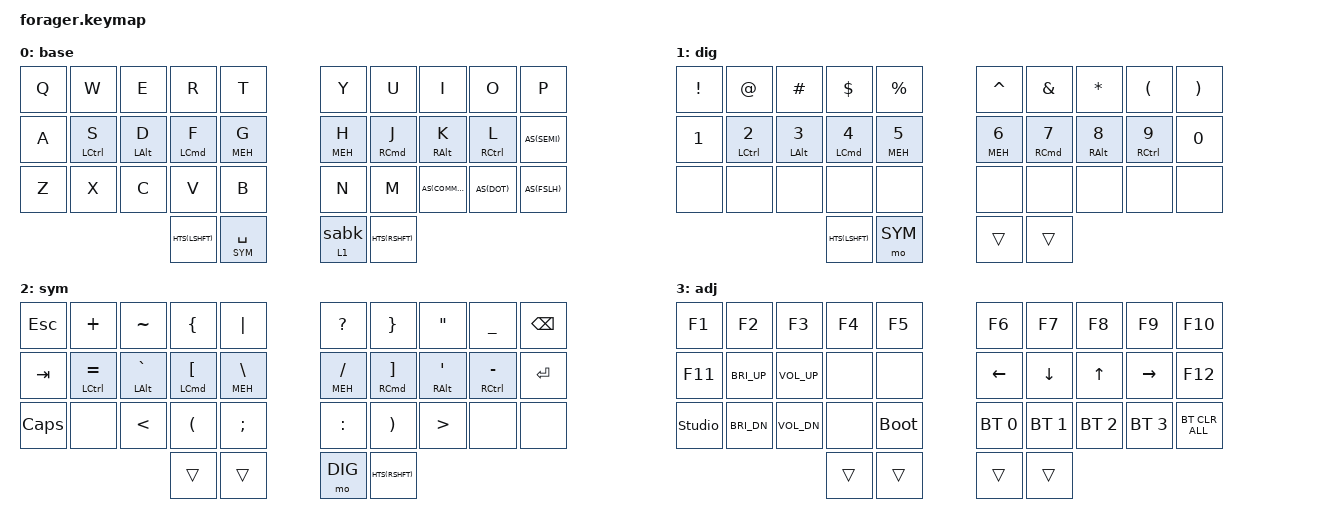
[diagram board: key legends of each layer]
#include <behaviors.dtsi>
#include <dt-bindings/zmk/keys.h>
#include <dt-bindings/zmk/bt.h>
#include <dt-bindings/zmk/outputs.h>

#define BASE 0
#define DIG  1
#define SYM  2
#define ADJ  3

#define AS(keycode) &as LS(keycode) keycode     // Autoshift Macro
#define HTS(keycode) &hts keycode keycode       // Hold tap sticky
#define MEH LS(LC(LALT))

/ {
    behaviors {
        as: auto_shift {
            compatible = "zmk,behavior-hold-tap";
            #binding-cells = <2>;
            tapping-term-ms = <250>;
            require-prior-idle-ms = <100>;
            flavor = "tap-preferred";
            bindings = <&kp>, <&kp>;
        };
        ht: hold_tap {
            compatible = "zmk,behavior-hold-tap";
            #binding-cells = <2>;
            tapping-term-ms = <200>;
            flavor = "balanced";
            bindings = <&kp>, <&kp>;
        };
        sabk: shift_to_alt_backspace {
            compatible = "zmk,behavior-mod-morph";
            #binding-cells = <0>;
            bindings = <&kp BSPC>, <&kp LA(BSPC)>;
            mods = <(MOD_LSFT|MOD_RSFT)>;
        };
        hts: hold_stiky_tap_shift {
            compatible = "zmk,behavior-hold-tap";
            #binding-cells = <2>;
            tapping-term-ms = <200>;
            flavor = "balanced";
            bindings = <&sk>, <&kp>;
        };
        sym_bspc: left_thumb_hold_tap {
            compatible = "zmk,behavior-hold-tap";
            #binding-cells = <2>;
            flavor = "tap-preferred";
            tapping-term-ms = <150>;
            quick-tap-ms = <200>;
            bindings = <&mo>, <&sabk>;
        };
        lhm: left_homerow_mods {
            compatible = "zmk,behavior-hold-tap";
            #binding-cells = <2>;
            flavor = "balanced";
            tapping-term-ms = <280>;
            quick-tap-ms = <175>;
            require-prior-idle-ms = <150>;
            bindings = <&kp>, <&kp>;
            hold-trigger-key-positions = <5 6 7 8 9 15 16 17 18 19 25 26 27 28 29 30 31 32 33>;
        };
        rhm: right_homerow_mods {
            compatible = "zmk,behavior-hold-tap";
            #binding-cells = <2>;
            flavor = "balanced";
            tapping-term-ms = <280>;
            quick-tap-ms = <175>;
            require-prior-idle-ms = <150>;
            bindings = <&kp>, <&kp>;
            hold-trigger-key-positions = <0 1 2 3 4 10 11 12 13 14 20 21 22 23 24 30 31 32 33>;
        };
    };

    combos {
        compatible = "zmk,combos";
        combo_caps {
            timeout-ms = <50>;
            key-positions = <30 33>; // Both shifts
            bindings = <&kp CAPS>;
        };
    };

    conditional_layers {
        compatible = "zmk,conditional-layers";
        tri_layer {
            if-layers = <1 2>;
            then-layer = <3>;
        };
    };

    keymap {
        compatible = "zmk,keymap";

        base {
            bindings = <
            &kp Q           &kp W           &kp E           &kp R           &kp T                                           &kp Y           &kp U           &kp I           &kp O           &kp P
            &kp A           &lhm LCTRL S    &lhm LALT D     &lhm LCMD F     &lhm MEH G                                      &rhm MEH H      &rhm RCMD J     &rhm RALT K     &rhm RCTRL L    AS(SEMI)
            &kp Z           &kp X           &kp C           &kp V           &kp B                                           &kp N           &kp M           AS(COMMA)       AS(DOT)         AS(FSLH)
                                                                            HTS(LSHFT)  &lt SYM SPACE      &sym_bspc 1 0    HTS(RSHFT)
            >;
        };

        dig {
            bindings = <
            /* &kp LS(N1)      &kp LS(N2)      &kp LS(N3)      &kp LS(N4)      &kp LS(N5)                                      &kp LS(N6)      &kp LS(N7)      &kp LS(N8)      &kp LS(N9)      &kp LS(N0) */
            &kp EXCL        &kp AT_SIGN     &kp HASH        &kp DOLLAR      &kp PERCENT                                     &kp CARET       &kp AMPS        &kp ASTRK       &kp LPAR        &kp RPAR
            &kp N1          &lhm LCTRL N2   &lhm LALT N3    &lhm LCMD N4    &lhm MEH N5                                     &rhm MEH N6     &rhm RCMD N7    &rhm RALT N8    &rhm RCTRL N9   &kp N0
            &none           &none           &none           &none           &none                                           &none           &none           &none           &none           &none 
                                                                            HTS(LSHFT)  &mo SYM            &trans           &trans
            >;
        };

        sym {
            bindings = <
            &kp ESC         &kp PLUS         &kp TILDE       &kp LBRC       &kp PIPE                                        &kp QMARK       &kp RBRC        &kp DQT          &kp UNDER        &kp BSPC
            &kp TAB         &lhm LCTRL EQUAL &lhm LALT GRAVE &lhm LCMD LBKT &lhm MEH BSLH                                   &rhm MEH FSLH   &rhm RCMD RBKT  &rhm RALT SQT    &rhm RCTRL MINUS &kp ENTER
            &kp CAPSLOCK    &none            &kp LESS_THAN   &kp LPAR       &kp SEMI                                        &kp COLON       &kp RPAR        &kp GREATER_THAN &none            &none 
                                                                            &trans          &trans           &mo DIG        HTS(RSHFT) 
            >;
        };

        adj {
            bindings = <
            &kp F1          &kp F2          &kp F3          &kp F4          &kp F5                                          &kp F6          &kp F7          &kp F8          &kp F9          &kp F10
            &kp F11         &kp C_BRI_UP    &kp C_VOL_UP    &none           &none                                           &kp LEFT        &kp DOWN        &kp UP          &kp RIGHT       &kp F12
            &studio_unlock  &kp C_BRI_DN    &kp C_VOL_DN    &none           &bootloader                                     &bt BT_SEL 0    &bt BT_SEL 1    &bt BT_SEL 2    &bt BT_SEL 3    &bt BT_CLR_ALL                                  
                                                                            &trans          &trans          &trans          &trans
            >;
        };
    };
};

&lt {
    // require-prior-idle-ms = <100>;
    tapping-term-ms = <150>;
    quick-tap-ms = <200>;
};

&mt {
    quick-tap-ms = <200>;
};

&sk {
    release-after-ms = <500>;
    quick-release;
};
